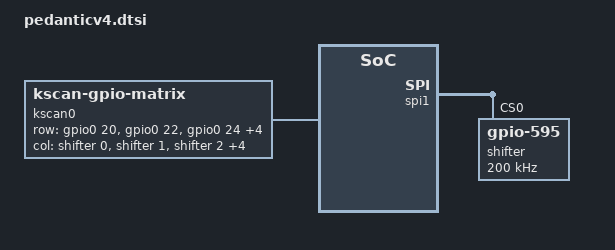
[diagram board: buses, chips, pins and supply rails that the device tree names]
#include <behaviors.dtsi>
#include <dt-bindings/zmk/matrix_transform.h>
#include <dt-bindings/zmk/keys.h>
#include "pedanticv4-transform.dtsi"
#include "pedanticv4-layouts.dtsi"

// Tell VIK that there is 1 other device on the SPI bus.
// You will need to increase this number if you add another SPI device.
#define VIK_SPI_REG_START 1
// Pulled out to an external variable so VIK can find the SPI bus.
#define VIK_SPI_CS_PREFIX <&gpio0 4 GPIO_ACTIVE_LOW>

&spi1 {
    status = "okay";
    cs-gpios = VIK_SPI_CS_PREFIX;

    shifter: 595@0 {
        compatible = "zmk,gpio-595";
        status = "okay";
        gpio-controller;
        spi-max-frequency = <200000>;
        reg = <0>;
        ngpios = <8>;
        #gpio-cells = <2>;
    };
};

/ {
    chosen {
        zmk,kscan = &kscan0;
        zmk,physical-layout = &default_layout;
    };

    kscan0: kscan_0 {
        compatible = "zmk,kscan-gpio-matrix";
        diode-direction = "col2row";

        row-gpios
            = <&gpio0 20 (GPIO_ACTIVE_HIGH | GPIO_PULL_DOWN)>
            , <&gpio0 22 (GPIO_ACTIVE_HIGH | GPIO_PULL_DOWN)>
            , <&gpio0 24 (GPIO_ACTIVE_HIGH | GPIO_PULL_DOWN)>
            , <&gpio0 9  (GPIO_ACTIVE_HIGH | GPIO_PULL_DOWN)>
            , <&gpio0 10 (GPIO_ACTIVE_HIGH | GPIO_PULL_DOWN)>
            , <&gpio1 13 (GPIO_ACTIVE_HIGH | GPIO_PULL_DOWN)>
            , <&gpio1 15 (GPIO_ACTIVE_HIGH | GPIO_PULL_DOWN)>
            ;

        col-gpios
            = <&shifter 0 GPIO_ACTIVE_HIGH>
            , <&shifter 1 GPIO_ACTIVE_HIGH>
            , <&shifter 2 GPIO_ACTIVE_HIGH>
            , <&shifter 3 GPIO_ACTIVE_HIGH>
            , <&shifter 4 GPIO_ACTIVE_HIGH>
            , <&shifter 5 GPIO_ACTIVE_HIGH>
            , <&shifter 6 GPIO_ACTIVE_HIGH>
            ;
    };
};

#include "pedanticv4-encoders.dtsi"
